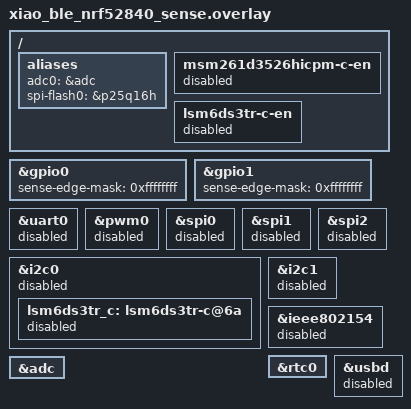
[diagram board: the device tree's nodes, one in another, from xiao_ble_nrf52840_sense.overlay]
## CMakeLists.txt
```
# SPDX-License-Identifier: Apache-2.0

cmake_minimum_required(VERSION 3.20.0)

find_package(Zephyr REQUIRED HINTS $ENV{ZEPHYR_BASE})
project(ble-triggerbox)

target_sources(app PRIVATE src/main.c src/trigger_ble.c src/storage_nvs.c src/battery.c)
```

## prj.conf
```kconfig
CONFIG_GPIO=y
CONFIG_STD_C23=y


CONFIG_BT=y
CONFIG_SETTINGS=y
CONFIG_BT_SMP=y
CONFIG_BT_SIGNING=y
CONFIG_BT_PERIPHERAL=y
CONFIG_BT_BAS=y

CONFIG_BT_DEVICE_NAME="UU_triggerbox"
CONFIG_BT_DEVICE_APPEARANCE=541
CONFIG_BT_DEVICE_NAME_DYNAMIC=n
CONFIG_BT_PRIVACY=n


#memory
CONFIG_FLASH=y
CONFIG_FLASH_PAGE_LAYOUT=y
CONFIG_FLASH_MAP=y
CONFIG_NVS=y
CONFIG_NORDIC_QSPI_NOR=y
CONFIG_NORDIC_QSPI_NOR_FLASH_LAYOUT_PAGE_SIZE=4096
CONFIG_HEAP_MEM_POOL_SIZE=2048
CONFIG_PM_DEVICE=y
#CONFIG_PARTITION_MANAGER_ENABLED=y
CONFIG_RING_BUFFER=y

#power
CONFIG_USB_DEVICE_STACK=n
CONFIG_POWEROFF=y


CONFIG_LOG=n
CONFIG_SERIAL=n
CONFIG_CONSOLE=n
CONFIG_USB_CDC_ACM_LOG_LEVEL_OFF=y


#battery
CONFIG_ADC=y
CONFIG_ADC_NRFX_SAADC=y
```

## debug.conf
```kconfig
#debug
CONFIG_LOG=y
CONFIG_RTT_CONSOLE=y
CONFIG_USE_SEGGER_RTT=y
CONFIG_CBPRINTF_FP_SUPPORT=y
CONFIG_CORTEX_M_DEBUG_MONITOR_HOOK=y
CONFIG_SEGGER_DEBUGMON=y
CONFIG_DEBUG_OPTIMIZATIONS=y
CONFIG_DEBUG_THREAD_INFO=y
CONFIG_LOG_FUNC_NAME_PREFIX_ERR=y

CONFIG_USB_CDC_ACM_LOG_LEVEL_OFF=n
```

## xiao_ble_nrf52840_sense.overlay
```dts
/*
 * Copyright (c) 2024 Centro de Inovacao EDGE
 *
 * SPDX-License-Identifier: Apache-2.0
 */

 / {
	// zephyr,user {
	// 	signal-gpios = <&gpio1 11 GPIO_ACTIVE_HIGH>;			
	// };

	aliases {
		adc0 = &adc;
        spi-flash0 = &p25q16h;	
			
	};
	
	msm261d3526hicpm-c-en {		
		status = "disabled";
	};

	lsm6ds3tr-c-en {
		status = "disabled";
	};

	// sw_en: ad7124-c-en {
	// 	compatible = "regulator-fixed-sync", "regulator-fixed";
	// 	enable-gpios = <&gpio1 11 (NRF_GPIO_DRIVE_S0H1 | GPIO_ACTIVE_HIGH)>;
	// 	regulator-name = "AD7124_C_EN";
	// 	// regulator-boot-on;
	// 	// startup-delay-us = <3000>;
	// };    
};

&gpio0 {
    status = "okay";
    sense-edge-mask = <0xffffffff>;
};

&gpio1 {
    status = "okay";
    sense-edge-mask = <0xffffffff>;
};

&uart0 {
    status = "disabled";
};

&pwm0 {
    status = "disabled"; 
};

&spi0 {
	status = "disabled";
};

&spi1 {
	status = "disabled";
};

&spi2 {    
	status = "disabled";	
};

&i2c0 {	
    lsm6ds3tr_c: lsm6ds3tr-c@6a {
        status = "disabled";
    };
	status = "disabled";
};

&i2c1 {
    status = "disabled";
};

&ieee802154 {
    status = "disabled";
};

&rtc0 {
	status = "okay";
};

&usbd {
    status = "disabled";
};

&adc {
	status = "okay";
	// #address-cells = <1>;
	// #size-cells = <0>;

	// channel@0 {
	// 	reg = <0>;
	// 	zephyr,gain = "ADC_GAIN_1";
	// 	zephyr,reference = "ADC_REF_INTERNAL";
	// 	zephyr,acquisition-time = <ADC_ACQ_TIME_DEFAULT>;
	// 	zephyr,input-positive = <NRF_SAADC_AIN1>; /* P0.03 */
	// 	zephyr,oversampling = <8>;
	// };

	// channel@1 {
	// 	reg = <1>;
	// 	zephyr,gain = "ADC_GAIN_1_6";
	// 	zephyr,reference = "ADC_REF_INTERNAL";
	// 	zephyr,acquisition-time = <ADC_ACQ_TIME_DEFAULT>;
	// 	zephyr,input-positive = <NRF_SAADC_VDD>;
	// 	zephyr,oversampling = <8>;
	// };
};

// &pinctrl {
//     qspi_default: qspi_default {
// 		group1 {
// 			psels = <NRF_PSEL(QSPI_SCK, 0, 21)>,
// 				<NRF_PSEL(QSPI_IO0, 0, 20)>,
// 				<NRF_PSEL(QSPI_IO1, 0, 24)>,
// 				<NRF_PSEL(QSPI_IO2, 0, 22)>,
// 				<NRF_PSEL(QSPI_IO3, 0, 23)>,
// 				<NRF_PSEL(QSPI_CSN, 0, 25)>;
// 		};
// 	};

// 	qspi_sleep: qspi_sleep {
// 		group1 {
// 			psels = <NRF_PSEL(QSPI_SCK, 0, 21)>,
// 				<NRF_PSEL(QSPI_IO0, 0, 20)>,
// 				<NRF_PSEL(QSPI_IO1, 0, 24)>,
// 				<NRF_PSEL(QSPI_IO2, 0, 22)>,
// 				<NRF_PSEL(QSPI_IO3, 0, 23)>;
// 			low-power-enable;
// 		};
//         group2 {
// 			psels = <NRF_PSEL(QSPI_CSN, 0, 25)>;
// 			low-power-enable;
// 			bias-pull-up;
// 		};
// 	};
//};
```

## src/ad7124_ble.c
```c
/*!
 *****************************************************************************
  @file:  ad7124_console_app.c

  @brief: Implementation for the menu functions that handle the AD7124

  @details:
 -----------------------------------------------------------------------------
Copyright (c) 2019 Analog Devices, Inc.  All rights reserved.
*/

#include <zephyr/kernel.h>
#include <zephyr/drivers/gpio.h>                                                                                                                                                     

#include <zephyr/logging/log.h>
#include <zephyr/pm/device.h>
#include <zephyr/settings/settings.h>
#include <zephyr/drivers/regulator.h>

#include <zephyr/bluetooth/bluetooth.h>
#include <zephyr/bluetooth/hci.h>
#include <zephyr/bluetooth/conn.h>
#include <zephyr/bluetooth/uuid.h>
#include <zephyr/bluetooth/gatt.h>

#include "nrfx.h"
#include "hal/nrf_gpio.h"


LOG_MODULE_REGISTER(AD7124_BLE, LOG_LEVEL_INF);


const struct device *const gpio0_dev = DEVICE_DT_GET(DT_NODELABEL(gpio0));
/*
 * @brief  Write generic device register (platform dependent)
 *
 * @param  handle    customizable argument. In this examples is used in
 *                   order to select the correct sensor bus handler.
 * @param  bufr      pointer to data to read in register reg
 * @param  bufw      pointer to data to write in register reg
 * @param  len       number of consecutive bytes to write
 *
 */

 //primary custom service 
static struct bt_uuid_128 uuid_triggerbox_prim = BT_UUID_INIT_128(
	BT_UUID_128_ENCODE(0xa6c47c93, 0x1112, 0x4ca6, 0x176e, 0xdffb871f11f0));

static struct bt_uuid_128 uuid_data = BT_UUID_INIT_128(
	BT_UUID_128_ENCODE(0x84b45e35, 0x140a, 0x4d32, 0x92c6, 0x386d8bff160d));


#define ble_buff_size (5*sizeof(uint32_t))
static uint8_t triggers_ble_buff[ble_buff_size]; //size of packed protobuf


static ssize_t read_ad_buffer(struct bt_conn *conn, const struct bt_gatt_attr *attr,
	void *buf, uint16_t len, uint16_t offset)
{	

	const uint8_t *value = attr->user_data;	

	return bt_gatt_attr_read(conn, attr, buf, len, offset, value, sizeof(triggers_ble_buff));
}

void ble_notify_adbuffer_proc(struct k_work *ptrWorker);
void configure_gpio_interrupt(struct k_work *work);

K_WORK_DEFINE(ble_notify_task, ble_notify_adbuffer_proc);
K_THREAD_STACK_DEFINE(my_stack_area, 1024);
K_WORK_DEFINE(enableNotifyTask, configure_gpio_interrupt);

static const struct device *gpio_dev;
static struct gpio_callback rdy_cb_data;

void rdy_handler(const struct device *dev, struct gpio_callback *cb, uint32_t pins)
{
    // Only trigger this when SPI is idle!
    uint32_t port_val = nrf_gpio_port_in_read(NRF_P0);
	//triggers_ble_buff = port_val :: think something smart:

	k_work_submit(&ble_notify_task);
    // Schedule SPI read from ADC here
}

void configure_gpio_interrupt(struct k_work *work)
{
    gpio_pin_configure(gpio0_dev, 2,GPIO_INPUT | GPIO_PULL_UP);
    gpio_pin_interrupt_configure(gpio_dev, 2, GPIO_INT_EDGE_TO_ACTIVE);

    gpio_init_callback(&rdy_cb_data, rdy_handler, BIT(2));
    gpio_add_callback(gpio_dev, &rdy_cb_data);
	//NVIC_EnableIRQ(GPIOTE_IRQn);
}

void disable_gpio_interrupt()
{    
	//NVIC_DisableIRQ(GPIOTE_IRQn);
	
    gpio_pin_interrupt_configure(gpio0_dev, 2, GPIO_INT_DISABLE);    
}


struct k_work_q my_work_q;



static uint8_t notify_ad_buffer_on = 0;

static void ble_ad_buffer_notify_changed(const struct bt_gatt_attr *attr, uint16_t value) {
	ARG_UNUSED(attr);
	LOG_INF("notify_changed: %d", value);
	notify_ad_buffer_on = (value == BT_GATT_CCC_NOTIFY) ? 1 : 0;
	if(value == BT_GATT_CCC_NOTIFY)	{
		LOG_INF("start listening to triggers");
		k_work_submit_to_queue(&my_work_q, &enableNotifyTask);		
		
		
	}
}


void ble_notify_adbuffer_proc(struct k_work *ptrWorker);



/* AD7124 readout primary Service Declaration */
BT_GATT_SERVICE_DEFINE(triggerbox_svc,
	BT_GATT_PRIMARY_SERVICE(&uuid_triggerbox_prim),
	
	// BT_GATT_CHARACTERISTIC(&uuid_identifier.uuid,
	// 		       BT_GATT_CHRC_READ | BT_GATT_CHRC_WRITE,
	// 		       BT_GATT_PERM_READ | BT_GATT_PERM_WRITE,
	// 		       read_identifier, write_identifier, uniqueIdentifier_value),	

	BT_GATT_CHARACTERISTIC(&uuid_data.uuid, 
	 		       BT_GATT_CHRC_READ | BT_GATT_CHRC_NOTIFY,
	 		       BT_GATT_PERM_READ,
	 		       read_ad_buffer, NULL, triggers_ble_buff),
	BT_GATT_CCC(ble_ad_buffer_notify_changed, BT_GATT_PERM_READ | BT_GATT_PERM_WRITE),
);

/// @brief Notify BLE when data ready
/// @param ptrWorker 
void ble_notify_adbuffer_proc(struct k_work *ptrWorker) {					
	if(!notify_ad_buffer_on) return;
	
	struct bt_gatt_attr *notify_attr = bt_gatt_find_by_uuid(triggerbox_svc.attrs, triggerbox_svc.attr_count, &uuid_data.uuid);	
	struct bt_gatt_notify_params params = {
        .attr = notify_attr,
        .data = triggers_ble_buff,
        .len  = sizeof(triggers_ble_buff),
      //  .func = notify_complete_cb, 
    };

	int ret = bt_gatt_notify_cb(NULL, &params);
	if(ret < 0) {
		LOG_ERR("error notify data %d", ret);
	}
}

//advertising data packet
const struct bt_data ad[] = {
	BT_DATA(BT_DATA_NAME_COMPLETE, CONFIG_BT_DEVICE_NAME, sizeof(CONFIG_BT_DEVICE_NAME) - 1),
	BT_DATA_BYTES(BT_DATA_FLAGS, (BT_LE_AD_GENERAL | BT_LE_AD_NO_BREDR)),
	BT_DATA_BYTES(BT_DATA_UUID16_ALL, BT_UUID_16_ENCODE(BT_UUID_BAS_VAL), BT_UUID_16_ENCODE(BT_UUID_CTS_VAL)),
};


static void connected(struct bt_conn *conn, uint8_t err)
{
	if (err) {
		LOG_INF("Connection failed (err 0x%02x)\n", err);
	} else {		
		LOG_INF("Connected\n");		
	}
}

static void disconnected(struct bt_conn *conn, uint8_t reason)
{
	LOG_INF("Disconnected (reason 0x%02x)\n", reason);	
}

BT_CONN_CB_DEFINE(conn_callbacks) = {
	.connected = connected,
	.disconnected = disconnected,	
};

#define BT_LE_ADV_CONN_CUSTOM BT_LE_ADV_PARAM(BT_LE_ADV_OPT_CONNECTABLE, \
	BT_GAP_ADV_FAST_INT_MIN_2*5, \
	BT_GAP_ADV_FAST_INT_MAX_2*5, NULL)
	
static void bt_ready(void)
{
	int err;

	LOG_INF("Bluetooth initialized\n");	

	if (IS_ENABLED(CONFIG_SETTINGS)) {
		settings_load();
	}

	err = bt_le_adv_start(BT_LE_ADV_CONN_CUSTOM, ad, ARRAY_SIZE(ad), NULL, 0);
	if (err) {
		LOG_ERR("Advertising failed to start (err %d)\n", err);
		return;
	}

	LOG_INF("Advertising successfully started\n");
}

static struct bt_conn_auth_cb auth_cb_display = {
	.passkey_display = NULL,// auth_passkey_display,
	.passkey_entry = NULL,
	.cancel = NULL,
	.passkey_confirm = NULL,	
};


static struct bt_gatt_cb gatt_callbacks = {
	
};

int ble_load(void)
{		
	k_work_queue_init(&my_work_q);

	k_work_queue_start(&my_work_q, my_stack_area,
					   K_THREAD_STACK_SIZEOF(my_stack_area), 95,
					   NULL);	

	LOG_INF("loading ble");
	int err;

	err = bt_enable(NULL);
	if (err) {
		LOG_INF("Bluetooth init failed (err %d)\n", err);
		return -EADV;
	}

	bt_ready();

	bt_gatt_cb_register(&gatt_callbacks);
	bt_conn_auth_cb_register(&auth_cb_display);

	//clean up bonds
	//bt_unpair(BT_ID_DEFAULT, BT_ADDR_LE_ANY);	
	
	return 0;
}

SYS_INIT(ble_load, APPLICATION, CONFIG_APPLICATION_INIT_PRIORITY);
```

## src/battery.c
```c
/*
 * Copyright 2024 Marcus Alexander Tjomsaas
 *
 * Licensed under the Apache License, Version 2.0 (the "License");
 * you may not use this file except in compliance with the License.
 * You may obtain a copy of the License at
 *
 *     http://www.apache.org/licenses/LICENSE-2.0
 *
 * Unless required by applicable law or agreed to in writing, software
 * distributed under the License is distributed on an "AS IS" BASIS,
 * WITHOUT WARRANTIES OR CONDITIONS OF ANY KIND, either express or implied.
 * See the License for the specific language governing permissions and
 * limitations under the License.
 */

#include "battery.h"
#include <zephyr/pm/device.h>
#include <zephyr/bluetooth/services/bas.h>
#include <zephyr/kernel.h>
#include <zephyr/device.h>
#include <zephyr/devicetree.h>
#include <zephyr/drivers/gpio.h>
#include <zephyr/drivers/adc.h>
#include <zephyr/logging/log.h>

LOG_MODULE_REGISTER(battery, LOG_LEVEL_INF);

static void update_ble_handler(struct k_work *work);

K_WORK_DELAYABLE_DEFINE(ble_send_work, update_ble_handler);


static int16_t sample_buffer[ADC_TOTAL_SAMPLES];

static struct adc_sequence_options options = {
    .extra_samplings = ADC_TOTAL_SAMPLES - 1,
    .interval_us = ADC_SAMPLE_INTERVAL_US,
};

static struct adc_sequence sequence = {
    .options = &options,
    .channels = BIT(ADC_CHANNEL),
    .buffer = sample_buffer,
    .buffer_size = sizeof(sample_buffer),
    .resolution = ADC_RESOLUTION,
};

static struct adc_channel_cfg channel_7_cfg = {
    .gain = ADC_GAIN,
    .reference = ADC_REFERENCE,
    .acquisition_time = ADC_ACQ_TIME_DEFAULT,
    .channel_id = ADC_CHANNEL,
#ifdef CONFIG_ADC_NRFX_SAADC
    .input_positive = ADC_PORT
#endif
};

// MCU peripherals for reading battery voltage
static const struct device *gpio_battery_dev = DEVICE_DT_GET(DT_NODELABEL(gpio0));
static const struct device *adc_battery_dev = DEVICE_DT_GET(DT_NODELABEL(adc));

// Charging interrupt

static K_MUTEX_DEFINE(battery_mut);

// Assuming LiPo battery.
// For better accuracy, use your battery's datasheet.
static BatteryState battery_states[] = {
    {4200, 100},
    {4160, 99},
    {4090, 91},
    {4030, 78},
    {3890, 63},
    {3830, 53},
    {3680, 36},
    {3660, 35},
    {3480, 14},
    {3420, 11},
    {3150, 1}, // 3240
    {0000, 0}  // Below safe level
};

int battery_get_millivolt(uint16_t *battery_millivolt)
{

    int ret = 0;

    // Voltage divider circuit (Should tune R1 in software if possible)
    const uint16_t R1 = 1037; // Originally 1M ohm, calibrated after measuring actual voltage values. Can happen due to resistor tolerances, temperature ect..
    const uint16_t R2 = 510;  // 510K ohm
    
    int adc_mv = 0;
    
    ret |= k_mutex_lock(&battery_mut, K_FOREVER);
    ret |= gpio_pin_set(gpio_battery_dev, GPIO_BATTERY_READ_ENABLE, 1);
    ret |= adc_read(adc_battery_dev, &sequence);
    uint16_t adc_vref = adc_ref_internal(adc_battery_dev);

    // Get average sample value.
    for (uint8_t sample = 0; sample < ADC_TOTAL_SAMPLES; sample++)
    {
        adc_mv += sample_buffer[sample]; // ADC value, not millivolt yet.
    }
    adc_mv /= ADC_TOTAL_SAMPLES;

    // Convert ADC value to millivolts
    ret |= adc_raw_to_millivolts(adc_vref, ADC_GAIN, ADC_RESOLUTION, &adc_mv);

    // Calculate battery voltage.
    *battery_millivolt = adc_mv * ((R1 + R2) / R2);

    ret |= gpio_pin_set(gpio_battery_dev, GPIO_BATTERY_READ_ENABLE, 0);

    k_mutex_unlock(&battery_mut);

    LOG_DBG("%d mV", *battery_millivolt);
    return ret;
}

int battery_get_percentage(uint8_t *battery_percentage, uint16_t battery_millivolt)
{

    // Ensure voltage is within bounds
    if (battery_millivolt > battery_states[0].voltage)
        *battery_percentage = 100;
    if (battery_millivolt < battery_states[ARRAY_SIZE(battery_states)-1].voltage)
        *battery_percentage = 0;

    for (uint8_t i = 0; i < ARRAY_SIZE(battery_states)-1; i++)
    {
        // Find the two points battery_millivolt is between
        if (battery_states[i].voltage >= battery_millivolt && battery_millivolt >= battery_states[i + 1].voltage)
        {
            // Linear interpolation
            *battery_percentage = battery_states[i].percentage +
                                  ((float)(battery_millivolt - battery_states[i].voltage) *
                                   ((float)(battery_states[i + 1].percentage - battery_states[i].percentage) /
                                    (float)(battery_states[i + 1].voltage - battery_states[i].voltage)));

            LOG_DBG("%d %%", *battery_percentage);
            return 0;
        }
    }
    return 0;
}


static void update_ble_handler(struct k_work *work) {
    
    uint8_t percentage = 0;
    uint16_t millivolt = 0;
    int err = 0;
   // err |= pm_device_action_run(adc_battery_dev, PM_DEVICE_ACTION_RESUME);
    err |= battery_get_millivolt(&millivolt);

    err |= battery_get_percentage(&percentage, millivolt);
    err |= bt_bas_set_battery_level(percentage);
    LOG_INF("update_ble mV %d, percentage %d", millivolt, percentage);
    
    //err |= pm_device_action_run(adc_battery_dev, PM_DEVICE_ACTION_SUSPEND);
    if(err != 0) {
        LOG_ERR("error %d", err);
    }
    k_work_schedule(&ble_send_work, K_SECONDS(BAS_UPDATE_FREQUENCY));
}

int battery_init()
{
    int ret = 0;

    ret |= adc_channel_setup(adc_battery_dev, &channel_7_cfg);        
    ret |= gpio_pin_configure(gpio_battery_dev, GPIO_BATTERY_READ_ENABLE, GPIO_OUTPUT | GPIO_ACTIVE_LOW);
     ret |= gpio_pin_configure(gpio_battery_dev, GPIO_BATTERY_CHARGE_SPEED, GPIO_OUTPUT | GPIO_ACTIVE_LOW);
    ret |= gpio_pin_set(gpio_battery_dev, GPIO_BATTERY_CHARGE_SPEED, 1); // FAST charge 100mA
    //ret |= pm_device_action_run(adc_battery_dev, PM_DEVICE_ACTION_SUSPEND);
    if(ret != 0) {
        LOG_ERR("error, %d", ret);
    } else {
        LOG_INF("Initialized");
    }
    
    k_work_schedule(&ble_send_work, K_SECONDS(BAS_UPDATE_FREQUENCY));

    return ret;
}

SYS_INIT(battery_init, APPLICATION, CONFIG_APPLICATION_INIT_PRIORITY);
```

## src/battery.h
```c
/*
 * Copyright 2024 Marcus Alexander Tjomsaas
 *
 * Licensed under the Apache License, Version 2.0 (the "License");
 * you may not use this file except in compliance with the License.
 * You may obtain a copy of the License at
 *
 *     http://www.apache.org/licenses/LICENSE-2.0
 *
 * Unless required by applicable law or agreed to in writing, software
 * distributed under the License is distributed on an "AS IS" BASIS,
 * WITHOUT WARRANTIES OR CONDITIONS OF ANY KIND, either express or implied.
 * See the License for the specific language governing permissions and
 * limitations under the License.
 */

#include <stdint.h>
#include <stdbool.h>

#ifndef __BATTERY_H__
#define __BATTERY_H__

#define BAS_UPDATE_FREQUENCY 120
#define GPIO_BATTERY_CHARGE_SPEED 13
#define GPIO_BATTERY_CHARGING_ENABLE 17
#define GPIO_BATTERY_READ_ENABLE 14

// Change this to a higher number for better averages
// Note that increasing this holds up the thread / ADC for longer.
#define ADC_TOTAL_SAMPLES 10

//--------------------------------------------------------------
// ADC setup

#define ADC_RESOLUTION 12
#define ADC_CHANNEL 7
#define ADC_PORT SAADC_CH_PSELP_PSELP_AnalogInput7 // AIN7
#define ADC_REFERENCE ADC_REF_INTERNAL             // 0.6V
#define ADC_GAIN ADC_GAIN_1_6                      // ADC REFERENCE * 6 = 3.6V
#define ADC_SAMPLE_INTERVAL_US 500                 // Time between each sample


typedef struct
{
    uint16_t voltage;
    uint8_t percentage;
} BatteryState;


/**
 * @brief Calculates the battery voltage using the ADC.
 *
 * @param[in] battery_millivolt Pointer to where battery voltage is stored.
 *
 * @retval 0 if successful. Negative errno number on error.
 */
int battery_get_millivolt(uint16_t *battery_millivolt);

/**
 * @brief Calculates the battery percentage using the battery voltage.
 *
 * @param[in] battery_percentage  Pointer to where battery percentage is stored.
 *
 * @param[in] battery_millivolt Voltage used to calculate the percentage of how much energy is left in a 3.7V LiPo battery.
 *
 * @retval 0 if successful. Negative errno number on error.
 */
int battery_get_percentage(uint8_t *battery_percentage, uint16_t battery_millivolt);


#endif
```

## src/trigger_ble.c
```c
#include <zephyr/kernel.h>
#include <zephyr/drivers/gpio.h>                                                                                                                                                     

#include <zephyr/sys/ring_buffer.h>
#include <zephyr/logging/log.h>
#include <zephyr/pm/device.h>
#include <zephyr/settings/settings.h>
#include <zephyr/drivers/regulator.h>


#include <zephyr/bluetooth/bluetooth.h>
#include <zephyr/bluetooth/hci.h>
#include <zephyr/bluetooth/conn.h>
#include <zephyr/bluetooth/uuid.h>
#include <zephyr/bluetooth/gatt.h>

#include "nrfx.h"
#include "hal/nrf_gpio.h"


LOG_MODULE_REGISTER(TRIGGERBOX_BLE, LOG_LEVEL_INF);


const struct device *const gpio_dev[2] = {DEVICE_DT_GET(DT_NODELABEL(gpio0)),DEVICE_DT_GET(DT_NODELABEL(gpio1))};

static struct bt_uuid_128 uuid_triggerbox_prim = BT_UUID_INIT_128(
	BT_UUID_128_ENCODE(0xa6c47c93, 0x1112, 0x4ca6, 0x176e, 0xdffb871f11f0));

static struct bt_uuid_128 uuid_data = BT_UUID_INIT_128(
	BT_UUID_128_ENCODE(0x84b45e35, 0x140a, 0x4d32, 0x92c6, 0x386d8bff160d));


static bool isConnected = 0;
static uint8_t triggers_ble_buff[50]; //size of packed protobuf


static ssize_t read_ad_buffer(struct bt_conn *conn, const struct bt_gatt_attr *attr,
	void *buf, uint16_t len, uint16_t offset)
{	

	const uint8_t *value = attr->user_data;	

	return bt_gatt_attr_read(conn, attr, buf, len, offset, value, sizeof(triggers_ble_buff));
}

void ble_notify_adbuffer_proc(struct k_work *ptrWorker);
void port_triggered_proc(struct k_work *worker);

void enable_gpio_interrupt(struct k_work *work);
void disable_gpio_interrupt(struct k_work *work);

K_WORK_DEFINE(work_ble_notify, ble_notify_adbuffer_proc);
K_WORK_DEFINE(work_porttrigger, port_triggered_proc);

K_WORK_DEFINE(work_enable_notify, enable_gpio_interrupt);
K_WORK_DEFINE(work_disable_notify, disable_gpio_interrupt); //todo:implement?


K_THREAD_STACK_DEFINE(threatstack_notifyen, 1024);
K_THREAD_STACK_DEFINE(threatstack_port_triggered, 4096);
K_THREAD_STACK_DEFINE(threatstack_ble_notify, 4096);


RING_BUF_DECLARE(ringbuf, 256);

struct k_work_q work_q_notify_enabler;
struct k_work_q work_q_port_trigger;
struct k_work_q work_q_ble_notify;

void rdy_handler(const struct device *dev, struct gpio_callback *cb, uint32_t pins)
{    		
	//SPARSE("triggerd by: %d", pins);
	k_work_submit_to_queue(&work_q_port_trigger, &work_porttrigger);		
}

static const uint8_t gpiopins0[6] = {2,3,4,5,28,29};
static const uint8_t gpiopins1[2] = {11,12};

static const uint8_t *gpiopinarrs[2] = {gpiopins0, gpiopins1};
static const uint8_t gpiosizes[2] = {6,2};

void configure_gpio()
{	
	//static struct gpio_callback rdy_cb_data_port0[ARRAY_SIZE(gpiopins0)];
	//static struct gpio_callback rdy_cb_data_port1[ARRAY_SIZE(gpiopins1)];

	//static struct gpio_callback *rdy_cb_data_ports[2] = {rdy_cb_data_port0, rdy_cb_data_port1};

	// for(int portnum = 0; portnum < 2; portnum++) {	
	// 	for(int pin = 0; pin < gpiosizes[portnum]; pin++) {
	// 		gpio_pin_configure(gpio_dev[portnum], gpiopinarrs[portnum][pin], GPIO_INPUT | GPIO_PULL_UP);    
	// 		gpio_init_callback(&rdy_cb_data_ports[portnum][pin], rdy_handler, BIT(gpiopinarrs[portnum][pin]));    	
	// 		gpio_add_callback(gpio_dev[portnum], &rdy_cb_data_ports[portnum][pin]);	
	// 	}
	// }
	for(int port = 0; port < 2; port++) {	
		gpio_port_pins_t gpio_masks[2] = {0};
		for(int pin = 0; pin < gpiosizes[port]; pin++) {
			gpio_masks[port] |= BIT(gpiopinarrs[port][pin]);
		}

		static struct gpio_callback gpio_cb_s[2];
		gpio_init_callback(&gpio_cb_s[port], rdy_handler, gpio_masks[port]);    
		gpio_add_callback(gpio_dev[port], &gpio_cb_s[port]);

	}
}

void enable_gpio_interrupt(struct k_work *work) {
	for(int portnum = 0; portnum < 2; portnum++) {	
		for(int pin = 0; pin < gpiosizes[portnum]; pin++) {	
			gpio_pin_configure(gpio_dev[portnum], gpiopinarrs[portnum][pin], GPIO_INPUT | GPIO_PULL_UP);    
			gpio_pin_interrupt_configure(gpio_dev[portnum], gpiopinarrs[portnum][pin], GPIO_INT_EDGE_BOTH);
		}
	}
}

void disable_gpio_interrupt(struct k_work *work)
{    
	for(int portnum = 0; portnum < 2; portnum++) {	
		for(int pin = 0; pin < gpiosizes[portnum]; pin++) {				
			gpio_pin_interrupt_configure(gpio_dev[portnum], gpiopinarrs[portnum][pin], GPIO_INT_DISABLE);
		}
	}	
}


static uint8_t notify_ad_buffer_on = 0;

static void ble_ad_buffer_notify_changed(const struct bt_gatt_attr *attr, uint16_t value) {
	ARG_UNUSED(attr);
	LOG_INF("notify_changed: %d", value);
	notify_ad_buffer_on = (value == BT_GATT_CCC_NOTIFY) ? 1 : 0;
	if(value == BT_GATT_CCC_NOTIFY || value == BT_GATT_CCC_INDICATE)	{
		LOG_INF("start listening to triggers");
		k_work_submit_to_queue(&work_q_notify_enabler, &work_enable_notify);						
	} else {
		LOG_INF("stop listening to triggers");
		k_work_submit_to_queue(&work_q_notify_enabler, &work_disable_notify);						
	}
}


void ble_notify_adbuffer_proc(struct k_work *ptrWorker);

BT_GATT_SERVICE_DEFINE(triggerbox_svc,
	BT_GATT_PRIMARY_SERVICE(&uuid_triggerbox_prim),
	
	BT_GATT_CHARACTERISTIC(&uuid_data.uuid, 
	 		       BT_GATT_CHRC_READ | BT_GATT_CHRC_NOTIFY,
	 		       BT_GATT_PERM_READ,
	 		       read_ad_buffer, NULL, triggers_ble_buff),
	BT_GATT_CCC(ble_ad_buffer_notify_changed, BT_GATT_PERM_READ | BT_GATT_PERM_WRITE),
);

K_MUTEX_DEFINE(MUT_porttrigger);
K_MUTEX_DEFINE(MUT_ble_notify);

void port_triggered_proc(struct k_work *worker) {
	
	if (k_mutex_lock(&MUT_porttrigger, K_MSEC(1)) == 0) {

		uint32_t port_val0 = nrf_gpio_port_in_read(NRF_P0);
		uint32_t port_val1 = nrf_gpio_port_in_read(NRF_P1);
		
		uint8_t portdata =\
			(port_val0 >> 2 & 0b11) |\
			(port_val0 >> 28 & 0b11) << 2 |\
			(port_val0 >> 4 & 0b11) << 4 | \
			(port_val1 >> 11 & 0b11) << 6;
						
		ring_buf_put(&ringbuf, &portdata, 1);
		k_mutex_unlock(&MUT_porttrigger);		
		LOG_INF("value to send: %d, port0: %d, port1: %d", portdata, port_val0, port_val1);
		k_work_submit_to_queue(&work_q_ble_notify, &work_ble_notify);
	} else {
		LOG_INF("could not aquire mutex");
	}
	
}

/// @brief Notify BLE when data ready
/// @param ptrWorker 
void ble_notify_adbuffer_proc(struct k_work *ptrWorker) {					
	LOG_INF("ble_notify");
	if(!isConnected) return;
	if(!notify_ad_buffer_on) return;
	if (k_mutex_lock(&MUT_ble_notify, K_NO_WAIT) == 0) {		
		LOG_INF("mutex aquired");
		uint8_t enqueued_ringbuffer = ring_buf_get(&ringbuf, triggers_ble_buff, sizeof(triggers_ble_buff));

		struct bt_gatt_attr *notify_attr = bt_gatt_find_by_uuid(triggerbox_svc.attrs, triggerbox_svc.attr_count, &uuid_data.uuid);	
		struct bt_gatt_notify_params params = {
			.attr = notify_attr,
			.data = triggers_ble_buff,
			.len  = enqueued_ringbuffer,
		    //.func = notify_complete_cb, 
		};

		int ret = bt_gatt_notify_cb(NULL, &params);
		if(ret < 0) {
			LOG_ERR("error notify data %d", ret);
		}
		
		LOG_INF("notifications send, amount: %d", enqueued_ringbuffer);
		k_sleep(K_MSEC(50));				
		k_mutex_unlock(&MUT_ble_notify);
		if(!ring_buf_is_empty(&ringbuf)){
			LOG_INF("ringbuf was filled after delay");
			k_work_submit_to_queue(&work_q_ble_notify, &work_ble_notify);			
		}		
	}	
}

//advertising data packet
const struct bt_data ad[] = {
	BT_DATA(BT_DATA_NAME_COMPLETE, CONFIG_BT_DEVICE_NAME, sizeof(CONFIG_BT_DEVICE_NAME) - 1),
	BT_DATA_BYTES(BT_DATA_FLAGS, (BT_LE_AD_GENERAL | BT_LE_AD_NO_BREDR)),
	BT_DATA_BYTES(BT_DATA_UUID16_ALL, BT_UUID_16_ENCODE(BT_UUID_BAS_VAL), BT_UUID_16_ENCODE(BT_UUID_CTS_VAL)),
};


static void connected(struct bt_conn *conn, uint8_t err)
{
	if (err) {
		LOG_INF("Connection failed (err 0x%02x)\n", err);
	} else {		
		isConnected = true;
		LOG_INF("Connected\n");		
	}
}

static void disconnected(struct bt_conn *conn, uint8_t reason)
{
	LOG_INF("Disconnected (reason 0x%02x)\n", reason);	
	isConnected = false;
}

BT_CONN_CB_DEFINE(conn_callbacks) = {
	.connected = connected,
	.disconnected = disconnected,	
};

#define BT_LE_ADV_CONN_CUSTOM BT_LE_ADV_PARAM(BT_LE_ADV_OPT_CONNECTABLE, \
	BT_GAP_ADV_FAST_INT_MIN_2*5, \
	BT_GAP_ADV_FAST_INT_MAX_2*5, NULL)
	
static void bt_ready(void)
{
	int err;

	LOG_INF("Bluetooth initialized\n");	

	if (IS_ENABLED(CONFIG_SETTINGS)) {
		settings_load();
	}

	err = bt_le_adv_start(BT_LE_ADV_CONN_CUSTOM, ad, ARRAY_SIZE(ad), NULL, 0);
	if (err) {
		LOG_ERR("Advertising failed to start (err %d)\n", err);
		return;
	}

	LOG_INF("Advertising successfully started\n");
}

static struct bt_conn_auth_cb auth_cb_display = {
	.passkey_display = NULL,// auth_passkey_display,
	.passkey_entry = NULL,
	.cancel = NULL,
	.passkey_confirm = NULL,	
};


static struct bt_gatt_cb gatt_callbacks = {
	
};

int initialize(void)
{		
	k_work_queue_init(&work_q_ble_notify);
	k_work_queue_init(&work_q_notify_enabler);
	k_work_queue_init(&work_q_port_trigger);

	k_work_queue_start(&work_q_notify_enabler, threatstack_notifyen,
					   K_THREAD_STACK_SIZEOF(threatstack_notifyen), 95,
					   NULL);	

	k_work_queue_start(&work_q_ble_notify, threatstack_ble_notify,
						K_THREAD_STACK_SIZEOF(threatstack_ble_notify), 96,
						NULL);	

	k_work_queue_start(&work_q_port_trigger, threatstack_port_triggered,
						K_THREAD_STACK_SIZEOF(threatstack_port_triggered), 97,
						NULL);	

	LOG_INF("loading ble");
	int err;

	err = bt_enable(NULL);
	if (err) {
		LOG_INF("Bluetooth init failed (err %d)\n", err);
		return -EADV;
	}

	bt_ready();

	bt_gatt_cb_register(&gatt_callbacks);
	bt_conn_auth_cb_register(&auth_cb_display);

	//clean up bonds
	//bt_unpair(BT_ID_DEFAULT, BT_ADDR_LE_ANY);	
	configure_gpio();
	
	return 0;
}

SYS_INIT(initialize, APPLICATION, CONFIG_APPLICATION_INIT_PRIORITY);
```
